# SIBG301M104LGL register map
Vendor: Silicon Labs; Series: Si; File version: B
Registers are 32-bit, read-write, reset 0x0 unless marked. A register's access mark holds for its fields unless they carry their own. Offsets are from the block's base; [hi:lo] are bit positions; {n}, {i} and the like mark numbered series.

## DMEM_NS — DMEM_NS Registers
Base 0x40808000
Same registers: DMEM_S 0x50808000
0x00 IPVERSION ro reset 0x1 — IPVERSION register signifies the version of the IP
  [1:0] IPVERSION — IP Version ID
0x04 CMD wo — Software Modifiable Command Register
  [0] CLEARECC — Clear ECCERRADDR and ECCMERRIND.MERRIND
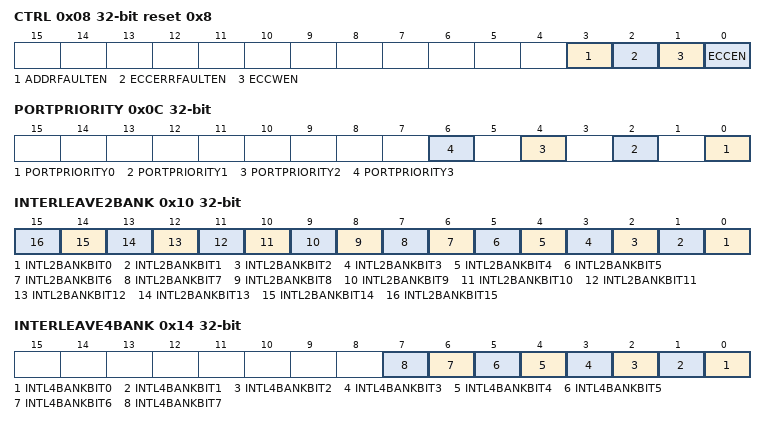
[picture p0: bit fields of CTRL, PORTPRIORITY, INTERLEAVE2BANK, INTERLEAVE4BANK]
0x08 CTRL reset 0x8 — Dynamically modifiable (When IP is running) Control Register
  [3] ADDRFAULTEN — Address fault bus fault enable
  [2] ECCERRFAULTEN — ECC Error bus fault enable
  [1] ECCWEN — Enable ECC syndrome writes
  [0] ECCEN — Enable ECC functionality
0x0C PORTPRIORITY — Port Arbitration Priority register
  [2n] PORTPRIORITY{n} (n=0..3) — Port{n} Arbitration Priority
0x10 INTERLEAVE2BANK — 2 Bank Interleaving Register.Each bit determines if two banks are interleaved.
  [n] INTL2BANKBIT{n} (n=0..15) — Per 2 bank interleaving bit
0x14 INTERLEAVE4BANK — 4 Bank Interleaving Register.Each bit determines if four banks are interleaved.
  [n] INTL4BANKBIT{n} (n=0..7) — Per 4 bank interleaving bit
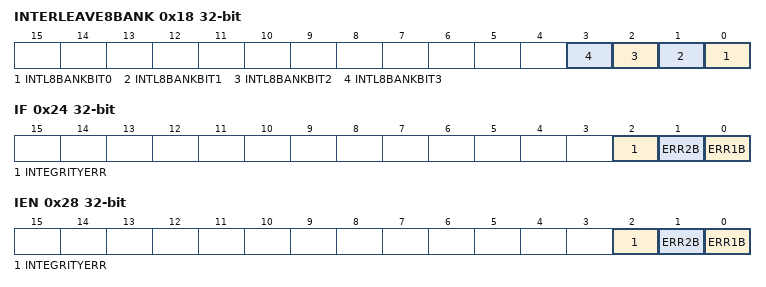
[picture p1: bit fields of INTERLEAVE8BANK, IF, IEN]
0x18 INTERLEAVE8BANK — 8 Bank Interleaving Register.Each bit determines if eight banks are interleaved.
  [n] INTL8BANKBIT{n} (n=0..3) — Per 8 bank interleaving bit
0x1C ECCERRADDR ro — Register indicating last captured ECC error address
  [31:0] ADDR — ECC Error Address
0x20 ECCMERRIND ro — This register indicates multiple ECC errors in the HYDRARAM
  [0] MERRIND — Multiple ECC errors on HYDRARAM
0x24 IF — ECC Error Interrupt Flag register
  [2] INTEGRITYERR — Integrity check error Interrupt flag
  [1] ERR2B — 2-bit ECC Error Interrupt Flag
  [0] ERR1B — 1-bit ECC Error Interrupt Flag
0x28 IEN — ECC Error Interrupt Enable register
  [2] INTEGRITYERR — Integrity check error Interrupt Enable
  [1] ERR2B — 2-bit ECC Error Interrupt Enable
  [0] ERR1B — 1-bit ECC Error Interrupt Enable
0x2C BANKSCACHEEN — RAM bank cache Enable register
  [31:0] BANKSCACHEEN — Enable bit for RAM bank caching

## DPLL0_NS — DPLL0_NS Registers
Base 0x4081C000
Same registers: DPLL0_S 0x5081C000
0x00 IPVERSION ro reset 0x1
  [31:0] IPVERSION — IP Version ID
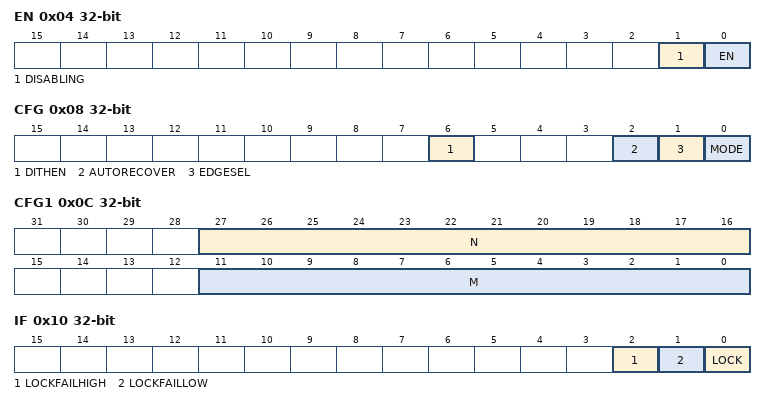
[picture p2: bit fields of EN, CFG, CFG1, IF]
0x04 EN
  [1] DISABLING ro — Disablement Busy Status
  [0] EN — Module Enable
0x08 CFG
  [6] DITHEN — Dither Enable Control
  [2] AUTORECOVER — Automatic Recovery Control
  [1] EDGESEL — Reference Edge Select
  [0] MODE — Operating Mode Control
    0=FLL (Frequency Lock Mode); 1=PLL (Phase Lock Mode)
0x0C CFG1
  [27:16] N — Factor N
  [11:0] M — Factor M
0x10 IF
  [2] LOCKFAILHIGH — Lock Failure High Interrupt Flag
  [1] LOCKFAILLOW — Lock Failure Low Interrupt Flag
  [0] LOCK — Lock Interrupt Flag
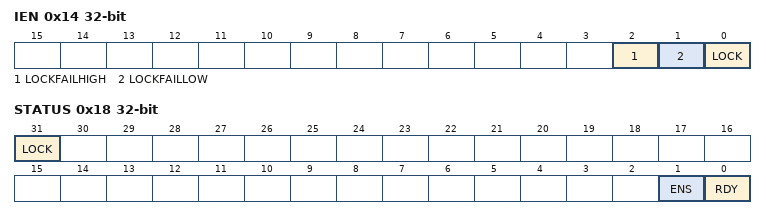
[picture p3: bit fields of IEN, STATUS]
0x14 IEN
  [2] LOCKFAILHIGH — LOCKFAILHIGH Interrupt Enable
  [1] LOCKFAILLOW — LOCKFAILLOW Interrupe Enable
  [0] LOCK — LOCK interrupt Enable
0x18 STATUS ro
  [31] LOCK — Lock Status
    0=UNLOCKED (DPLL is unlocked); 1=LOCKED (DPLL is locked)
  [1] ENS — Enable Status
  [0] RDY — Ready Status
0x24 LOCK wo reset 0x7102
  [15:0] LOCKKEY
    0x7102=UNLOCK (Unlock code)

## EMU_NS_CFGNS — EMU_NS_CFGNS Registers
Base 0xA300C000
Same registers: EMU_S_CFGNS 0xB300C000
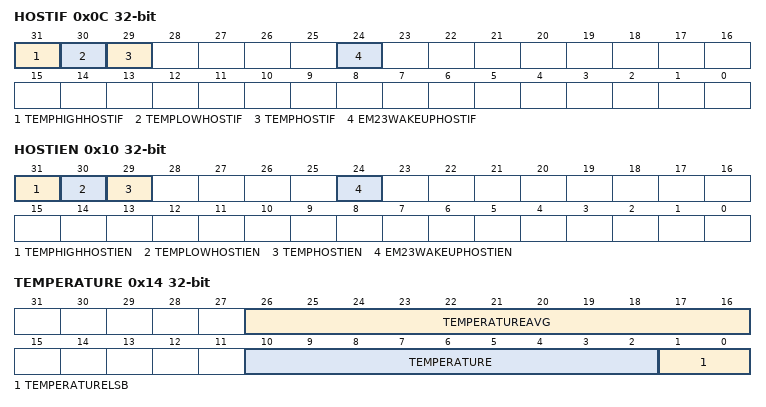
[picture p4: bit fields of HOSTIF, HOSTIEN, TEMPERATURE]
0x0C HOSTIF
  [31] TEMPHIGHHOSTIF — Temperature high Interrupt flag
  [30] TEMPLOWHOSTIF — Temperature low Interrupt flag
  [29] TEMPHOSTIF — Temperature Interrupt flag
  [24] EM23WAKEUPHOSTIF — EM23 Wake up Interrupt flag
0x10 HOSTIEN
  [31] TEMPHIGHHOSTIEN — Temperature high Interrupt enable
  [30] TEMPLOWHOSTIEN — Temperature low Interrupt enable
  [29] TEMPHOSTIEN — Temperature Interrupt enable
  [24] EM23WAKEUPHOSTIEN — EM23 Wake up Interrupt enable
0x14 TEMPERATURE ro
  [26:16] TEMPERATUREAVG — Averaged Temperature
  [10:2] TEMPERATURE — Temperature measured
  [1:0] TEMPERATURELSB — Temperature measured decimal part
